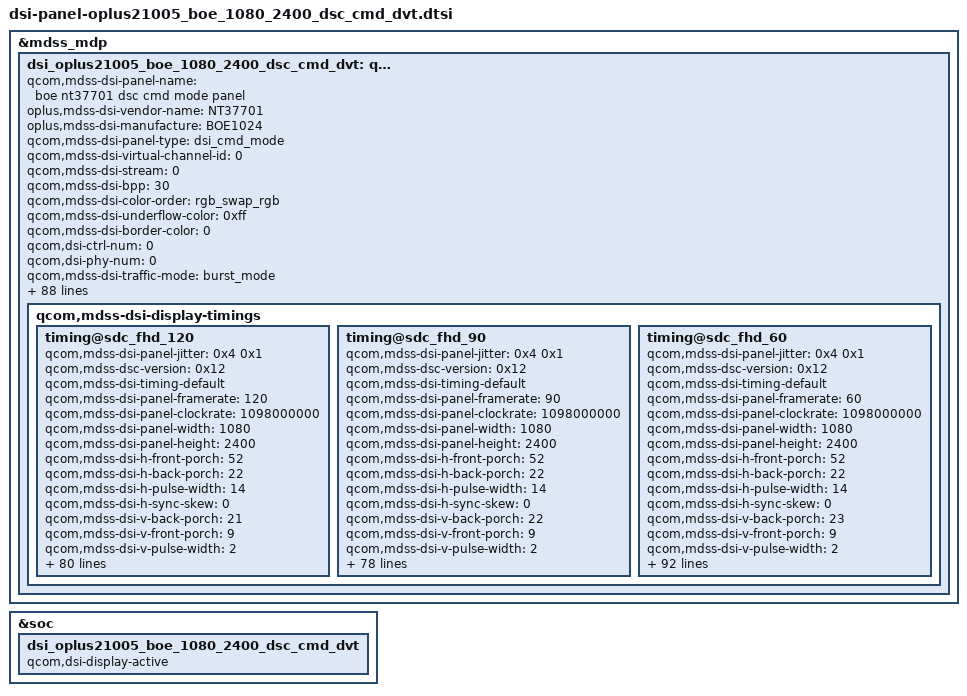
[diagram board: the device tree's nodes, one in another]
&mdss_mdp {
	dsi_oplus21005_boe_1080_2400_dsc_cmd_dvt: qcom,mdss_dsi_oplus21005_boe_1080_2400_dsc_cmd_dvt {
		qcom,mdss-dsi-panel-name = "boe nt37701 dsc cmd mode panel";
		oplus,mdss-dsi-vendor-name = "NT37701";
		oplus,mdss-dsi-manufacture = "BOE1024";
		qcom,mdss-dsi-panel-type = "dsi_cmd_mode";
		qcom,mdss-dsi-virtual-channel-id = <0>;
		qcom,mdss-dsi-stream = <0>;
		qcom,mdss-dsi-bpp = <30>;
		qcom,mdss-dsi-color-order = "rgb_swap_rgb";
		qcom,mdss-dsi-underflow-color = <0xff>;
		qcom,mdss-dsi-border-color = <0>;
		qcom,dsi-ctrl-num = <0>;
		qcom,dsi-phy-num = <0>;
		qcom,mdss-dsi-traffic-mode = "burst_mode";
		qcom,mdss-dsi-lane-map = "lane_map_0123";
		qcom,mdss-dsi-bllp-eof-power-mode;
		qcom,mdss-dsi-bllp-power-mode;
		qcom,mdss-dsi-lane-0-state;
		qcom,mdss-dsi-lane-1-state;
		qcom,mdss-dsi-lane-2-state;
		qcom,mdss-dsi-lane-3-state;
		qcom,mdss-dsi-dma-trigger = "trigger_sw";
		qcom,mdss-loading-effect;
		qcom,mdss-dsi-mdp-trigger = "none";
		qcom,mdss-dsi-reset-sequence = <1 2>, <0 5>, <1 10>;
		qcom,mdss-dsi-te-pin-select = <1>;
		qcom,mdss-dsi-te-dcs-command = <1>;
		qcom,mdss-pan-physical-width-dimension = <68>;
		qcom,mdss-pan-physical-height-dimension = <152>;
		qcom,mdss-dsi-init-delay-us = <1000>;
		qcom,mdss-dsi-te-check-enable;
		qcom,mdss-dsi-te-using-te-pin;
		qcom,mdss-dsi-lp11-init;
		qcom,mdss-dsi-wr-mem-start = <0x2c>;
		qcom,mdss-dsi-wr-mem-continue = <0x3c>;
		qcom,mdss-dsi-panel-jitter = <0x4 0x1>;
		//qcom,mdss-dsc-scr-version = <0x1>;
		qcom,mdss-bl-high2bit;
		/* HDR Setting */
		qcom,mdss-dsi-panel-hdr-enabled;
		qcom,mdss-dsi-panel-hdr-color-primaries = <15635 16450 34000 16000 13250 34500 7500 3000>;
		qcom,mdss-dsi-panel-peak-brightness = <5400000>;
		qcom,mdss-dsi-panel-average-brightness = <2000000>;
		qcom,mdss-dsi-panel-blackness-level = <4000>;

		qcom,esd-check-enabled;
		oplus,esd-check-flag-enabled;
		qcom,mdss-dsi-panel-status-check-mode = "reg_read";
		qcom,mdss-dsi-panel-status-command = [
				06 01 00 01 05 00 02 0A 00
			];
		qcom,mdss-dsi-panel-status-command-state = "dsi_lp_mode";
		qcom,mdss-dsi-panel-status-value = <0x9C>;
		qcom,mdss-dsi-panel-status-read-length = <1>;


		qcom,dynamic-mode-switch-enabled;
		qcom,dynamic-mode-switch-type = "dynamic-resolution-switch-immediate";
		qcom,mdss-dsi-display-timings {
			timing@sdc_fhd_120{
				//qcom,mdss-mdp-transfer-time-us = <7700>;
				qcom,mdss-dsi-panel-jitter = <0x4 0x1>;
				//qcom,mdss-dsc-scr-version = <0x1>;
				qcom,mdss-dsc-version = <0x12>;
				qcom,mdss-dsi-timing-default;
				qcom,mdss-dsi-panel-framerate = <120>;
				//qcom,mdss-dsi-panel-clockrate = <825600000>;
				//qcom,mdss-dsi-panel-clockrate = <960800000>;
				//qcom,mdss-dsi-panel-clockrate = <900000000>;
				qcom,mdss-dsi-panel-clockrate = <1098000000>;
				qcom,mdss-dsi-panel-width = <1080>;
				qcom,mdss-dsi-panel-height = <2400>;

				qcom,mdss-dsi-h-front-porch = <52>;
				qcom,mdss-dsi-h-back-porch = <22>;
				qcom,mdss-dsi-h-pulse-width = <14>;
				qcom,mdss-dsi-h-sync-skew = <0>;
				qcom,mdss-dsi-v-back-porch = <21>;
				qcom,mdss-dsi-v-front-porch = <9>;
				qcom,mdss-dsi-v-pulse-width = <2>;
				qcom,mdss-dsi-h-sync-pulse = <0>;

				qcom,mdss-dsi-h-left-border = <0>;
				qcom,mdss-dsi-h-right-border = <0>;
				qcom,mdss-dsi-v-top-border = <0>;
				qcom,mdss-dsi-v-bottom-border = <0>;

				/* Apollo vsync config, need to measure TE signal */
				oplus,apollo-panel-vsync-width = <2000>;
				oplus,apollo-panel-vsync-period = <8300>;

				qcom,dsi-select-clocks = "mux_byte_clk0", "mux_pixel_clk0";

				oplus,fod-on-vblank = <0>;
				oplus,fod-off-vblank = <0>;
				qcom,mdss-dsi-panel-read-register-open-command = [
					39 01 00 00 00 00 03 F0 5A 5A
					];
				qcom,mdss-dsi-panel-id1-command = [
					06 01 00 00 00 00 01 E9
					];
				qcom,mdss-dsi-panel-read-register-close-command = [
					39 01 00 00 00 00 03 F0 A5 A5
					];
				qcom,mdss-dsi-timing-switch-command = [
					39 01 00 00 00 00 02 2F 03
				];
				qcom,mdss-dsi-on-command=[
					39 01 00 00 00 00 05 FF AA 55 A5 81
					39 01 00 00 00 00 02 6F 0F
					39 01 00 00 00 00 03 FD 01 80
					//39 01 00 00 00 00 06 F0 55 AA 52 08 01
					//39 01 00 00 00 00 08 C3 99 01 98 D0 22 02 00
					//39 01 00 00 00 00 06 F0 55 AA 52 08 01
					//39 01 00 00 00 00 08 C3 97 01 91 D0 22 02 00
					39 01 00 00 00 00 06 F0 55 AA 52 08 01
					39 01 00 00 00 00 08 C3 9C 01 90 D0 22 02 00
					39 01 00 00 00 00 05 FF AA 55 A5 80
					39 01 00 00 00 00 02 35 00
					39 01 00 00 00 00 02 53 20
					39 01 00 00 00 00 05 51 00 00 0F FE
					39 01 00 00 00 00 05 2A 00 00 04 37
					39 01 00 00 00 00 05 2B 00 00 09 5F
					//39 01 00 00 00 00 13 91 89 28 00 14 C2 00 03 1C 02 8C 00 0F 05 0E 02 8B 10 F0
					39 01 00 00 00 00 13 91 AB 2A 00 14 C2 00 02 B0 03 2A 00 15 05 0E 03 1D 0C F0
					39 01 00 00 00 00 02 03 01
					39 01 00 00 00 00 02 90 01
					05 01 00 00 00 00 02 2C 00
					/* Dither off */
					//39 01 00 00 00 00 06 F0 55 AA 52 08 00
					//39 01 00 00 00 00 10 B2 11 00 20 20 00 08 08 00 00 40 30 00 00 00 00

					39 01 00 00 00 00 06 F0 55 AA 52 08 00
					39 01 00 00 00 00 03 B2 11 63

					// SPR setting,pixel layout=GG2R2B
					39 01 00 00 00 00 06 F0 55 AA 52 08 07
					39 01 00 00 00 00 06 B0 8C C0 78 70 00
					39 01 00 00 00 00 06 B1 0c 1c 00 1c 0c
					39 01 00 00 00 00 0A B2 D2 D2 D2 D2 D2 D2 D2 D2 D2
					15 01 00 00 00 00 02 6F 36
					39 01 00 00 00 00 13 B2 32 32 32 32 32 32 32 32 32 05 05 05 05 05 05 05 05 05
					15 01 00 00 00 00 02 6F 09
					39 01 00 00 00 00 0A B2 D2 D2 D2 D2 D2 D2 D2 D2 D2
					15 01 00 00 00 00 02 6F 48
					39 01 00 00 00 00 13 B2 33 33 33 33 33 33 33 33 33 05 05 05 05 05 05 05 05 05
					15 01 00 00 00 00 02 6F 12
					39 01 00 00 00 00 0A B2 00 00 00 00 00 00 00 00 00
					15 01 00 00 00 00 02 6F 5A
					39 01 00 00 00 00 13 B2 04 04 04 04 04 04 04 04 04 04 04 04 04 04 04 04 04 04

					15 01 00 00 00 00 02 6F 1B
					39 01 00 00 00 00 0A B2 D2 D2 D2 D2 D2 D2 D2 D2 D2
					15 01 00 00 00 00 02 6F 6C
					39 01 00 00 00 00 13 B2 33 33 33 33 33 33 33 33 33 05 05 05 05 05 05 05 05 05

					15 01 00 00 00 00 02 6F 24
					39 01 00 00 00 00 0A B2 D2 D2 D2 D2 D2 D2 D2 D2 D2
					15 01 00 00 00 00 02 6F 7E
					39 01 00 00 00 00 13 B2 32 32 32 32 32 32 32 32 32 05 05 05 05 05 05 05 05 05

					15 01 00 00 00 00 02 6F 2D
					39 01 00 00 00 00 0A B2 00 00 00 00 00 00 00 00 00
					15 01 00 00 00 00 02 6F 90
					39 01 00 00 00 00 13 B2 04 04 04 04 04 04 04 04 04 04 04 04 04 04 04 04 04 04
					39 01 00 00 00 00 03 B7 00 00

					// SPR panel boundary decolor
					15 01 00 00 00 00 02 B4 C0
					15 01 00 00 00 00 02 6F 01
					39 01 00 00 00 00 0D B4 80 70 80 75 35 80 30 80 75 80 60 80

					// SPR FT OFF
					39 01 00 00 00 00 03 B7 00 00

					39 01 00 00 00 00 02 82 AE
					//39 01 00 00 00 00 02 8B 80
					39 01 00 00 00 00 02 2F 03
					39 01 00 00 00 00 06 F0 55 AA 52 08 01
					39 01 00 00 00 00 03 CD 05 81
					39 01 00 00 00 00 02 6F 10
					39 01 00 00 00 00 02 D8 14
					39 01 00 00 00 00 06 F0 55 AA 52 08 00
					39 01 00 00 00 00 02 6F 01
					39 01 00 00 00 00 02 C0 B3
					39 01 00 00 00 00 05 FF AA 55 A5 80
					39 01 00 00 00 00 02 6F 2E
					39 01 00 00 00 00 02 FB D1
					05 01 00 00 78 00 02 11 00
				];
				qcom,mdss-dsi-post-on-backlight = [
					/* Display On */
					05 01 00 00 00 00 02 29 00
				];
				qcom,mdss-dsi-off-command=[
					39 01 00 00 00 00 06 F0 55 AA 52 08 01
					15 01 00 00 00 00 02 CE 0C
					05 01 00 00 0A 00 02 28 00
					05 01 00 00 FA 00 02 10 00
				];
				qcom,mdss-dsi-lp1-command = [
					/* Panel OFF */
					05 01 00 00 11 00 01 28
					/* AOD Mode ON Setting */
					39 01 00 00 00 00 06 F0 55 AA 52 08 00
					15 01 00 00 00 00 02 6F 0D
					15 01 00 00 00 00 02 B5 50
					15 01 00 00 00 00 02 2F 01
					05 01 00 00 00 00 01 39
					05 01 00 00 14 00 01 2C
					15 01 00 00 00 00 02 65 01
					05 01 00 00 00 00 01 29
				];
				qcom,mdss-dsi-nolp-command = [
					/* AOD OFF */
					39 01 00 00 00 00 06 F0 55 AA 52 08 00
					15 01 00 00 00 00 02 6F 0D
					15 01 00 00 00 00 02 B5 4F
					15 01 00 00 00 00 02 65 00
					05 01 00 00 00 00 01 38
					05 01 00 00 14 00 01 2C
					15 01 00 00 00 00 02 2F 03

					/* ELVSS DIM OFF
					39 01 00 00 00 00 03 F0 5A 5A
					39 01 00 00 00 00 04 B0 00 0C 63
					15 01 00 00 00 00 02 63 00
					39 01 00 00 00 00 03 F0 A5 A5*/

					/* HBM OFF Mode
					39 01 00 00 00 00 06 F0 55 AA 52 08 00
					15 01 00 00 00 00 02 B2 11 */
				];
				qcom,mdss-dsi-aod-hbm-on-command = [
					/* Loading OFF
					39 00 00 00 00 00 03 F0 5A 5A
					39 00 00 00 00 00 04 B0 02 B6 1D
					39 00 00 00 00 00 02 1D 05
					39 01 00 00 00 00 03 F0 A5 A5*/
					/* AOD OFF */
					39 01 00 00 00 00 06 F0 55 AA 52 08 00
					15 01 00 00 00 00 02 6F 0D
					15 01 00 00 00 00 02 B5 4F
					15 01 00 00 00 00 02 65 00
					05 01 00 00 00 00 01 38
					05 01 00 00 00 00 01 2C
					/* AOR 1.6%
					39 00 00 00 00 00 03 F0 5A 5A
					39 00 00 00 00 00 04 B0 00 01 BD
					39 00 00 00 00 00 02 BD 02
					39 00 00 00 00 00 04 B0 02 b9 65
					39 00 00 00 00 00 07 65 00 AC 00 AC 00 AC
					39 00 00 00 00 00 02 F7 0F
					39 01 00 00 00 00 03 F0 A5 A5*/
					/* Hbm ON */
					39 01 00 00 00 00 03 51 0F FF
				];
				qcom,mdss-dsi-aod-hbm-off-command = [
					/* HBM OFF Mode
					39 01 00 00 00 00 06 F0 55 AA 52 08 00
					15 01 00 00 00 00 02 B2 11 */
				    /* AOD ON */
					39 01 00 00 00 00 06 F0 55 AA 52 08 00
					15 01 00 00 00 00 02 6F 0D
					15 01 00 00 00 00 02 B5 50
					15 01 00 00 00 00 02 2F 01
					05 01 00 00 00 00 01 39
					05 01 00 00 14 00 01 2C
					15 01 00 00 00 00 02 65 01
					05 01 00 00 00 00 01 29
					/* AOD 50nit */
					39 01 00 00 00 00 06 F0 55 AA 52 08 00
					15 01 00 00 00 00 02 6F 26
					39 01 00 00 00 00 0B B4 04 A2 04 A2 04 A2 04 A2 04 A2
				];
				qcom,mdss-dsi-hbm-off-command = [
					/* HBM OFF Mode
					39 01 00 00 00 00 06 F0 55 AA 52 08 00
					15 01 00 00 00 00 02 B2 11 */
				];
				qcom,mdss-dsi-hbm-on-command = [
					39 01 00 00 00 00 03 51 0F FF
				];
				qcom,mdss-dsi-normal-hbm-on-command = [
					39 01 00 00 00 00 03 51 0F FF
				];
				qcom,mdss-dsi-hbm-enter-switch-command = [
					39 01 00 00 00 00 03 51 0F FF
				];
				qcom,mdss-dsi-hbm-exit-switch-command = [
					/* HBM OFF Mode
					39 01 00 00 00 00 06 F0 55 AA 52 08 00
					15 01 00 00 00 00 02 B2 11 */
				];
				qcom,mdss-dsi-aor-restore-command = [
					/* AOR 16% */
					39 00 00 00 00 00 03 f0 5a 5a
					39 00 00 00 00 00 04 b0 00 01 bd
					39 00 00 00 00 00 02 bd 02
					39 00 00 00 00 00 04 b0 02 b9 65
					39 00 00 00 00 00 07 65 01 5e 01 5e 01 5e
					39 00 00 00 00 00 02 f7 0f
					39 01 00 00 00 00 03 f0 a5 a5
				];
				qcom,mdss-dsi-aod-high-mode-command = [
					/* AOD 50nit */
					39 01 00 00 00 00 06 F0 55 AA 52 08 00
					15 01 00 00 00 00 02 6F 26
					39 01 00 00 00 00 0B B4 04 A2 04 A2 04 A2 04 A2 04 A2
				];
				qcom,mdss-dsi-aod-low-mode-command = [
					/* AOD 10nit */
					39 01 00 00 00 00 06 F0 55 AA 52 08 00
					15 01 00 00 00 00 02 6F 26
					39 01 00 00 00 00 0B B4 08 8A 08 8A 08 8A 08 8A 08 8A
				];
				qcom,mdss-dsi-esd-switch-page-command = [
					39 01 00 00 00 00 05 FF AA 55 A5 81
					15 01 00 00 00 00 02 6F 0F
				];

				qcom,mdss-dsi-aod-hbm-on-command-state = "dsi_hs_mode";
				qcom,mdss-dsi-aod-hbm-off-command-state = "dsi_hs_mode";
				qcom,mdss-dsi-timing-switch-command-state = "dsi_hs_mode";
				qcom,mdss-dsi-on-command-state = "dsi_lp_mode";
				qcom,mdss-dsi-off-command-state = "dsi_hs_mode";
				/*
				qcom,mdss-dsi-seed-off-command-state = "dsi_hs_mode";
				qcom,mdss-dsi-seed-0-command-state = "dsi_hs_mode";
				qcom,mdss-dsi-seed-1-command-state = "dsi_hs_mode";
				qcom,mdss-dsi-seed-2-command-state = "dsi_hs_mode";
				qcom,mdss-dsi-loading-effect-1-command-state = "dsi_hs_mode";
				qcom,mdss-dsi-loading-effect-2-command-state = "dsi_hs_mode";
				qcom,mdss-dsi-loading-effect-off-command-state = "dsi_hs_mode";
				*/
				qcom,mdss-dsi-hbm-on-command-state = "dsi_hs_mode";
				qcom,mdss-dsi-hbm-off-command-state = "dsi_hs_mode";
				qcom,mdss-dsi-aor-restore-command-state = "dsi_hs_mode";

				//qcom,lm-split = <540 540>;
				qcom,compression-mode = "dsc";
				//qcom,mdss-dsc-encoders = <2>;
				qcom,mdss-dsc-slice-height = <20>;
				qcom,mdss-dsc-slice-width = <1080>;
				qcom,mdss-dsc-slice-per-pkt = <1>;
				qcom,mdss-dsc-bit-per-component = <10>;
				qcom,mdss-dsc-bit-per-pixel = <10>;
				qcom,mdss-dsc-block-prediction-enable;
				qcom,mdss-dsi-panel-id1-command-state = "dsi_lp_mode";
				qcom,mdss-dsi-panel-read-register-open-state = "dsi_lp_mode";
				qcom,mdss-dsi-panel-read-register-close-state = "dsi_lp_mode";
			};
			timing@sdc_fhd_90{
				//qcom,mdss-mdp-transfer-time-us = <7700>;
				qcom,mdss-dsi-panel-jitter = <0x4 0x1>;
				//qcom,mdss-dsc-scr-version = <0x1>;
				qcom,mdss-dsc-version = <0x12>;
				qcom,mdss-dsi-timing-default;
				qcom,mdss-dsi-panel-framerate = <90>;
				//qcom,mdss-dsi-panel-clockrate = <825600000>;
				//qcom,mdss-dsi-panel-clockrate = <960800000>;
				//qcom,mdss-dsi-panel-clockrate = <900000000>;
				qcom,mdss-dsi-panel-clockrate = <1098000000>;
				qcom,mdss-dsi-panel-width = <1080>;
				qcom,mdss-dsi-panel-height = <2400>;

				qcom,mdss-dsi-h-front-porch = <52>;
				qcom,mdss-dsi-h-back-porch = <22>;
				qcom,mdss-dsi-h-pulse-width = <14>;
				qcom,mdss-dsi-h-sync-skew = <0>;
				qcom,mdss-dsi-v-back-porch = <22>;
				qcom,mdss-dsi-v-front-porch = <9>;
				qcom,mdss-dsi-v-pulse-width = <2>;
				qcom,mdss-dsi-h-sync-pulse = <0>;

				qcom,mdss-dsi-h-left-border = <0>;
				qcom,mdss-dsi-h-right-border = <0>;
				qcom,mdss-dsi-v-top-border = <0>;
				qcom,mdss-dsi-v-bottom-border = <0>;

				qcom,dsi-select-clocks = "mux_byte_clk0", "mux_pixel_clk0";

				oplus,fod-on-vblank = <0>;
				oplus,fod-off-vblank = <0>;
				qcom,mdss-dsi-panel-read-register-open-command = [
					39 01 00 00 00 00 03 F0 5A 5A
					];
				qcom,mdss-dsi-panel-id1-command = [
					06 01 00 00 00 00 01 E9
					];
				qcom,mdss-dsi-panel-read-register-close-command = [
					39 01 00 00 00 00 03 F0 A5 A5
					];
				qcom,mdss-dsi-timing-switch-command = [
					39 01 00 00 02 00 02 2F 02
				];
				qcom,mdss-dsi-on-command=[
					39 01 00 00 00 00 05 FF AA 55 A5 81
					39 01 00 00 00 00 02 6F 0F
					39 01 00 00 00 00 03 FD 01 80
					//39 01 00 00 00 00 06 F0 55 AA 52 08 01
					//39 01 00 00 00 00 08 C3 99 01 98 D0 22 02 00
					//39 01 00 00 00 00 06 F0 55 AA 52 08 01
					//39 01 00 00 00 00 08 C3 97 01 91 D0 22 02 00
					39 01 00 00 00 00 06 F0 55 AA 52 08 01
					39 01 00 00 00 00 08 C3 9C 01 90 D0 22 02 00
					39 01 00 00 00 00 05 FF AA 55 A5 80
					39 01 00 00 00 00 02 35 00
					39 01 00 00 00 00 02 53 20
					39 01 00 00 00 00 05 51 00 00 0F FE
					39 01 00 00 00 00 05 2A 00 00 04 37
					39 01 00 00 00 00 05 2B 00 00 09 5F
					//39 01 00 00 00 00 13 91 89 28 00 14 C2 00 03 1C 02 8C 00 0F 05 0E 02 8B 10 F0
					39 01 00 00 00 00 13 91 AB 2A 00 14 C2 00 02 B0 03 2A 00 15 05 0E 03 1D 0C F0
					39 01 00 00 00 00 02 03 01
					39 01 00 00 00 00 02 90 01
					05 01 00 00 00 00 02 2C 00
					/* Dither off */
					//39 01 00 00 00 00 06 F0 55 AA 52 08 00
					//39 01 00 00 00 00 10 B2 11 00 20 20 00 08 08 00 00 40 30 00 00 00 00

					39 01 00 00 00 00 06 F0 55 AA 52 08 00
					39 01 00 00 00 00 03 B2 11 63

					// SPR setting,pixel layout=GG2R2B
					39 01 00 00 00 00 06 F0 55 AA 52 08 07
					39 01 00 00 00 00 06 B0 8C C0 78 70 00
					39 01 00 00 00 00 06 B1 0c 1c 00 1c 0c
					39 01 00 00 00 00 0A B2 D2 D2 D2 D2 D2 D2 D2 D2 D2
					15 01 00 00 00 00 02 6F 36
					39 01 00 00 00 00 13 B2 32 32 32 32 32 32 32 32 32 05 05 05 05 05 05 05 05 05
					15 01 00 00 00 00 02 6F 09
					39 01 00 00 00 00 0A B2 D2 D2 D2 D2 D2 D2 D2 D2 D2
					15 01 00 00 00 00 02 6F 48
					39 01 00 00 00 00 13 B2 33 33 33 33 33 33 33 33 33 05 05 05 05 05 05 05 05 05
					15 01 00 00 00 00 02 6F 12
					39 01 00 00 00 00 0A B2 00 00 00 00 00 00 00 00 00
					15 01 00 00 00 00 02 6F 5A
					39 01 00 00 00 00 13 B2 04 04 04 04 04 04 04 04 04 04 04 04 04 04 04 04 04 04

					15 01 00 00 00 00 02 6F 1B
					39 01 00 00 00 00 0A B2 D2 D2 D2 D2 D2 D2 D2 D2 D2
					15 01 00 00 00 00 02 6F 6C
					39 01 00 00 00 00 13 B2 33 33 33 33 33 33 33 33 33 05 05 05 05 05 05 05 05 05

					15 01 00 00 00 00 02 6F 24
					39 01 00 00 00 00 0A B2 D2 D2 D2 D2 D2 D2 D2 D2 D2
					15 01 00 00 00 00 02 6F 7E
					39 01 00 00 00 00 13 B2 32 32 32 32 32 32 32 32 32 05 05 05 05 05 05 05 05 05

					15 01 00 00 00 00 02 6F 2D
					39 01 00 00 00 00 0A B2 00 00 00 00 00 00 00 00 00
					15 01 00 00 00 00 02 6F 90
					39 01 00 00 00 00 13 B2 04 04 04 04 04 04 04 04 04 04 04 04 04 04 04 04 04 04
					39 01 00 00 00 00 03 B7 00 00

					// SPR panel boundary decolor
					15 01 00 00 00 00 02 B4 C0
					15 01 00 00 00 00 02 6F 01
					39 01 00 00 00 00 0D B4 80 70 80 75 35 80 30 80 75 80 60 80

					// SPR FT OFF
					39 01 00 00 00 00 03 B7 00 00

					39 01 00 00 00 00 02 82 AE
					//39 01 00 00 00 00 02 8B 80
					39 01 00 00 00 00 02 2F 02
					39 01 00 00 00 00 06 F0 55 AA 52 08 01
					39 01 00 00 00 00 03 CD 05 81
					39 01 00 00 00 00 02 6F 10
					39 01 00 00 00 00 02 D8 14
					39 01 00 00 00 00 06 F0 55 AA 52 08 00
					39 01 00 00 00 00 02 6F 01
					39 01 00 00 00 00 02 C0 B3
					39 01 00 00 00 00 05 FF AA 55 A5 80
					39 01 00 00 00 00 02 6F 2E
					39 01 00 00 00 00 02 FB D1
					05 01 00 00 78 00 02 11 00
				];
				qcom,mdss-dsi-post-on-backlight = [
					/* Display On */
					05 01 00 00 00 00 02 29 00
				];
				qcom,mdss-dsi-off-command=[
					39 01 00 00 00 00 06 F0 55 AA 52 08 01
					15 01 00 00 00 00 02 CE 0C
					05 01 00 00 0A 00 02 28 00
					05 01 00 00 FA 00 02 10 00
				];
				qcom,mdss-dsi-lp1-command = [
					/* Panel OFF */
					05 01 00 00 11 00 01 28
					/* AOD Mode ON Setting */
					39 01 00 00 00 00 06 F0 55 AA 52 08 00
					15 01 00 00 00 00 02 6F 0D
					15 01 00 00 00 00 02 B5 50
					15 01 00 00 00 00 02 2F 01
					05 01 00 00 00 00 01 39
					05 01 00 00 14 00 01 2C
					15 01 00 00 00 00 02 65 01
					05 01 00 00 00 00 01 29
				];
				qcom,mdss-dsi-nolp-command = [
					/* AOD OFF */
					39 01 00 00 00 00 06 F0 55 AA 52 08 00
					15 01 00 00 00 00 02 6F 0D
					15 01 00 00 00 00 02 B5 4F
					15 01 00 00 00 00 02 65 00
					05 01 00 00 00 00 01 38
					05 01 00 00 00 00 01 2C
					15 01 00 00 00 00 02 2F 02

					/* ELVSS DIM OFF
					39 01 00 00 00 00 03 F0 5A 5A
					39 01 00 00 00 00 04 B0 00 0C 63
					15 01 00 00 00 00 02 63 00
					39 01 00 00 00 00 03 F0 A5 A5*/

					/* HBM OFF Mode
					39 01 00 00 00 00 06 F0 55 AA 52 08 00
					15 01 00 00 00 00 02 B2 11 */
				];
				qcom,mdss-dsi-aod-hbm-on-command = [
					/* Loading OFF
					39 00 00 00 00 00 03 F0 5A 5A
					39 00 00 00 00 00 04 B0 02 B6 1D
					39 00 00 00 00 00 02 1D 05
					39 01 00 00 00 00 03 F0 A5 A5*/
					/* AOD OFF */
					39 01 00 00 00 00 06 F0 55 AA 52 08 00
					15 01 00 00 00 00 02 6F 0D
					15 01 00 00 00 00 02 B5 4F
					15 01 00 00 00 00 02 65 00
					05 01 00 00 00 00 01 38
					05 01 00 00 00 00 01 2C
					/* AOR 1.6%
					39 00 00 00 00 00 03 F0 5A 5A
					39 00 00 00 00 00 04 B0 00 01 BD
					39 00 00 00 00 00 02 BD 02
					39 00 00 00 00 00 04 B0 02 b9 65
					39 00 00 00 00 00 07 65 00 AC 00 AC 00 AC
					39 00 00 00 00 00 02 F7 0F
					39 01 00 00 00 00 03 F0 A5 A5*/
					/* Hbm ON */
					39 01 00 00 00 00 03 51 0F FF
				];
				qcom,mdss-dsi-aod-hbm-off-command = [
					/* HBM OFF Mode
					39 01 00 00 00 00 06 F0 55 AA 52 08 00
					15 01 00 00 00 00 02 B2 11 */
					/* AOD ON */
					39 01 00 00 00 00 06 F0 55 AA 52 08 00
					15 01 00 00 00 00 02 6F 0D
					15 01 00 00 00 00 02 B5 50
					15 01 00 00 00 00 02 2F 01
					05 01 00 00 00 00 01 39
					05 01 00 00 14 00 01 2C
					15 01 00 00 00 00 02 65 01
					05 01 00 00 00 00 01 29
					/* AOD 50nit */
					39 01 00 00 00 00 06 F0 55 AA 52 08 00
					15 01 00 00 00 00 02 6F 26
					39 01 00 00 00 00 0B B4 04 A2 04 A2 04 A2 04 A2 04 A2
				];
				qcom,mdss-dsi-hbm-off-command = [
					/* HBM OFF Mode
					39 01 00 00 00 00 06 F0 55 AA 52 08 00
					15 01 00 00 00 00 02 B2 11 */
				];
				qcom,mdss-dsi-hbm-on-command = [
					39 01 00 00 00 00 03 51 0F FF
				];
				qcom,mdss-dsi-normal-hbm-on-command = [
					39 01 00 00 00 00 03 51 0F FF
				];
				qcom,mdss-dsi-hbm-enter-switch-command = [
					39 01 00 00 00 00 03 51 0F FF
				];
				qcom,mdss-dsi-hbm-exit-switch-command = [
					/* HBM OFF Mode
					39 01 00 00 00 00 06 F0 55 AA 52 08 00
					15 01 00 00 00 00 02 B2 11 */
				];
				qcom,mdss-dsi-aor-restore-command = [
					/* AOR 16% */
					39 00 00 00 00 00 03 f0 5a 5a
					39 00 00 00 00 00 04 b0 00 01 bd
					39 00 00 00 00 00 02 bd 02
					39 00 00 00 00 00 04 b0 02 b9 65
					39 00 00 00 00 00 07 65 01 5e 01 5e 01 5e
					39 00 00 00 00 00 02 f7 0f
					39 01 00 00 00 00 03 f0 a5 a5
				];
				qcom,mdss-dsi-aod-high-mode-command = [
					/* AOD 50nit */
					39 01 00 00 00 00 06 F0 55 AA 52 08 00
					15 01 00 00 00 00 02 6F 26
					39 01 00 00 00 00 0B B4 04 A2 04 A2 04 A2 04 A2 04 A2
				];
				qcom,mdss-dsi-aod-low-mode-command = [
					/* AOD 10nit */
					39 01 00 00 00 00 06 F0 55 AA 52 08 00
					15 01 00 00 00 00 02 6F 26
					39 01 00 00 00 00 0B B4 08 8A 08 8A 08 8A 08 8A 08 8A
				];
				qcom,mdss-dsi-esd-switch-page-command = [
					39 01 00 00 00 00 05 FF AA 55 A5 81
					15 01 00 00 00 00 02 6F 0F
				];

				qcom,mdss-dsi-aod-hbm-on-command-state = "dsi_hs_mode";
				qcom,mdss-dsi-aod-hbm-off-command-state = "dsi_hs_mode";
				qcom,mdss-dsi-timing-switch-command-state = "dsi_hs_mode";
				qcom,mdss-dsi-on-command-state = "dsi_lp_mode";
				qcom,mdss-dsi-off-command-state = "dsi_hs_mode";
				/*
				qcom,mdss-dsi-seed-off-command-state = "dsi_hs_mode";
				qcom,mdss-dsi-seed-0-command-state = "dsi_hs_mode";
				qcom,mdss-dsi-seed-1-command-state = "dsi_hs_mode";
				qcom,mdss-dsi-seed-2-command-state = "dsi_hs_mode";
				qcom,mdss-dsi-loading-effect-1-command-state = "dsi_hs_mode";
				qcom,mdss-dsi-loading-effect-2-command-state = "dsi_hs_mode";
				qcom,mdss-dsi-loading-effect-off-command-state = "dsi_hs_mode";
				*/
				qcom,mdss-dsi-hbm-on-command-state = "dsi_hs_mode";
				qcom,mdss-dsi-hbm-off-command-state = "dsi_hs_mode";
				qcom,mdss-dsi-aor-restore-command-state = "dsi_hs_mode";

				//qcom,lm-split = <540 540>;
				qcom,compression-mode = "dsc";
				//qcom,mdss-dsc-encoders = <2>;
				qcom,mdss-dsc-slice-height = <20>;
				qcom,mdss-dsc-slice-width = <1080>;
				qcom,mdss-dsc-slice-per-pkt = <1>;
				qcom,mdss-dsc-bit-per-component = <10>;
				qcom,mdss-dsc-bit-per-pixel = <10>;
				qcom,mdss-dsc-block-prediction-enable;
				qcom,mdss-dsi-panel-id1-command-state = "dsi_lp_mode";
				qcom,mdss-dsi-panel-read-register-open-state = "dsi_lp_mode";
				qcom,mdss-dsi-panel-read-register-close-state = "dsi_lp_mode";
			};
			timing@sdc_fhd_60{
				//qcom,mdss-mdp-transfer-time-us = <7700>;
				qcom,mdss-dsi-panel-jitter = <0x4 0x1>;
				//qcom,mdss-dsc-scr-version = <0x1>;
				qcom,mdss-dsc-version = <0x12>;
				qcom,mdss-dsi-timing-default;
				qcom,mdss-dsi-panel-framerate = <60>;
				//qcom,mdss-dsi-panel-clockrate = <825600000>;
				//qcom,mdss-dsi-panel-clockrate = <960800000>;
				//qcom,mdss-dsi-panel-clockrate = <900000000>;
				qcom,mdss-dsi-panel-clockrate = <1098000000>;
				qcom,mdss-dsi-panel-width = <1080>;
				qcom,mdss-dsi-panel-height = <2400>;

				qcom,mdss-dsi-h-front-porch = <52>;
				qcom,mdss-dsi-h-back-porch = <22>;
				qcom,mdss-dsi-h-pulse-width = <14>;
				qcom,mdss-dsi-h-sync-skew = <0>;
				qcom,mdss-dsi-v-back-porch = <23>;
				qcom,mdss-dsi-v-front-porch = <9>;
				qcom,mdss-dsi-v-pulse-width = <2>;
				qcom,mdss-dsi-h-sync-pulse = <0>;

				qcom,mdss-dsi-h-left-border = <0>;
				qcom,mdss-dsi-h-right-border = <0>;
				qcom,mdss-dsi-v-top-border = <0>;
				qcom,mdss-dsi-v-bottom-border = <0>;

				/* Apollo vsync config, need to measure TE signal */
				oplus,apollo-panel-vsync-width = <13000>;
				oplus,apollo-panel-vsync-period = <16600>;

				qcom,dsi-select-clocks = "mux_byte_clk0", "mux_pixel_clk0";

				oplus,fod-on-vblank = <0>;
				oplus,fod-off-vblank = <0>;
				qcom,mdss-dsi-panel-read-register-open-command = [
					39 01 00 00 00 00 03 F0 5A 5A
					];
				qcom,mdss-dsi-panel-id1-command = [
					06 01 00 00 00 00 01 E9
					];
				qcom,mdss-dsi-panel-read-register-close-command = [
					39 01 00 00 00 00 03 F0 A5 A5
					];
				qcom,mdss-dsi-timing-switch-command = [
					39 01 00 00 02 00 02 2F 01
					];
				qcom,mdss-dsi-on-command=[
					39 01 00 00 00 00 05 FF AA 55 A5 81
					39 01 00 00 00 00 02 6F 0F
					39 01 00 00 00 00 03 FD 01 80
					//39 01 00 00 00 00 06 F0 55 AA 52 08 01
					//39 01 00 00 00 00 08 C3 99 01 98 D0 22 02 00
					//39 01 00 00 00 00 06 F0 55 AA 52 08 01
					//39 01 00 00 00 00 08 C3 97 01 91 D0 22 02 00
					39 01 00 00 00 00 06 F0 55 AA 52 08 01
					39 01 00 00 00 00 08 C3 9C 01 90 D0 22 02 00
					39 01 00 00 00 00 05 FF AA 55 A5 80
					39 01 00 00 00 00 02 35 00
					39 01 00 00 00 00 02 53 20
					39 01 00 00 00 00 05 51 00 00 0F FE
					39 01 00 00 00 00 05 2A 00 00 04 37
					39 01 00 00 00 00 05 2B 00 00 09 5F
					//39 01 00 00 00 00 13 91 89 28 00 14 C2 00 03 1C 02 8C 00 0F 05 0E 02 8B 10 F0
					39 01 00 00 00 00 13 91 AB 2A 00 14 C2 00 02 B0 03 2A 00 15 05 0E 03 1D 0C F0
					39 01 00 00 00 00 02 03 01
					39 01 00 00 00 00 02 90 01
					05 01 00 00 00 00 02 2C 00
					/* Dither off */
					//39 01 00 00 00 00 06 F0 55 AA 52 08 00
					//39 01 00 00 00 00 10 B2 11 00 20 20 00 08 08 00 00 40 30 00 00 00 00

					39 01 00 00 00 00 06 F0 55 AA 52 08 00
					39 01 00 00 00 00 03 B2 11 63

					// SPR setting,pixel layout=GG2R2B
					39 01 00 00 00 00 06 F0 55 AA 52 08 07
					39 01 00 00 00 00 06 B0 8C C0 78 70 00
					39 01 00 00 00 00 06 B1 0c 1c 00 1c 0c
					39 01 00 00 00 00 0A B2 D2 D2 D2 D2 D2 D2 D2 D2 D2
					15 01 00 00 00 00 02 6F 36
					39 01 00 00 00 00 13 B2 32 32 32 32 32 32 32 32 32 05 05 05 05 05 05 05 05 05
					15 01 00 00 00 00 02 6F 09
					39 01 00 00 00 00 0A B2 D2 D2 D2 D2 D2 D2 D2 D2 D2
					15 01 00 00 00 00 02 6F 48
					39 01 00 00 00 00 13 B2 33 33 33 33 33 33 33 33 33 05 05 05 05 05 05 05 05 05
					15 01 00 00 00 00 02 6F 12
					39 01 00 00 00 00 0A B2 00 00 00 00 00 00 00 00 00
					15 01 00 00 00 00 02 6F 5A
					39 01 00 00 00 00 13 B2 04 04 04 04 04 04 04 04 04 04 04 04 04 04 04 04 04 04

					15 01 00 00 00 00 02 6F 1B
					39 01 00 00 00 00 0A B2 D2 D2 D2 D2 D2 D2 D2 D2 D2
					15 01 00 00 00 00 02 6F 6C
					39 01 00 00 00 00 13 B2 33 33 33 33 33 33 33 33 33 05 05 05 05 05 05 05 05 05

					15 01 00 00 00 00 02 6F 24
					39 01 00 00 00 00 0A B2 D2 D2 D2 D2 D2 D2 D2 D2 D2
					15 01 00 00 00 00 02 6F 7E
					39 01 00 00 00 00 13 B2 32 32 32 32 32 32 32 32 32 05 05 05 05 05 05 05 05 05

					15 01 00 00 00 00 02 6F 2D
					39 01 00 00 00 00 0A B2 00 00 00 00 00 00 00 00 00
					15 01 00 00 00 00 02 6F 90
					39 01 00 00 00 00 13 B2 04 04 04 04 04 04 04 04 04 04 04 04 04 04 04 04 04 04
					39 01 00 00 00 00 03 B7 00 00

					// SPR panel boundary decolor
					15 01 00 00 00 00 02 B4 C0
					15 01 00 00 00 00 02 6F 01
					39 01 00 00 00 00 0D B4 80 70 80 75 35 80 30 80 75 80 60 80

					// SPR FT OFF
					39 01 00 00 00 00 03 B7 00 00

					39 01 00 00 00 00 02 82 AE
					//39 01 00 00 00 00 02 8B 80
					39 01 00 00 00 00 02 2F 01
					39 01 00 00 00 00 06 F0 55 AA 52 08 01
					39 01 00 00 00 00 03 CD 05 81
					39 01 00 00 00 00 02 6F 10
					39 01 00 00 00 00 02 D8 14
					39 01 00 00 00 00 06 F0 55 AA 52 08 00
					39 01 00 00 00 00 02 6F 01
					39 01 00 00 00 00 02 C0 B3
					39 01 00 00 00 00 05 FF AA 55 A5 80
					39 01 00 00 00 00 02 6F 2E
					39 01 00 00 00 00 02 FB D1
					05 01 00 00 78 00 02 11 00
				];
				qcom,mdss-dsi-post-on-backlight = [
					/* Display On */
					05 01 00 00 00 00 02 29 00
				];
				qcom,mdss-dsi-off-command=[
					39 01 00 00 00 00 06 F0 55 AA 52 08 01
					15 01 00 00 00 00 02 CE 0C
					05 01 00 00 0A 00 02 28 00
					05 01 00 00 FA 00 02 10 00
				];
				qcom,mdss-dsi-lp1-command = [
					/* Panel OFF */
					05 01 00 00 11 00 01 28
					/* AOD Mode ON Setting */
					39 01 00 00 00 00 06 F0 55 AA 52 08 00
					15 01 00 00 00 00 02 6F 0D
					15 01 00 00 00 00 02 B5 50
					15 01 00 00 00 00 02 2F 01
					05 01 00 00 00 00 01 39
					05 01 00 00 14 00 01 2C
					15 01 00 00 00 00 02 65 01
					05 01 00 00 00 00 01 29
				];
				qcom,mdss-dsi-nolp-command = [
					/* AOD OFF */
					39 01 00 00 00 00 06 F0 55 AA 52 08 00
					15 01 00 00 00 00 02 6F 0D
					15 01 00 00 00 00 02 B5 4F
					15 01 00 00 00 00 02 65 00
					05 01 00 00 00 00 01 38
					05 01 00 00 00 00 01 2C
					15 01 00 00 00 00 02 2F 01

					/* ELVSS DIM OFF
					39 01 00 00 00 00 03 F0 5A 5A
					39 01 00 00 00 00 04 B0 00 0C 63
					15 01 00 00 00 00 02 63 00
					39 01 00 00 00 00 03 F0 A5 A5*/

					/* HBM OFF Mode
					39 01 00 00 00 00 06 F0 55 AA 52 08 00
					15 01 00 00 00 00 02 B2 11 */
				];
				qcom,mdss-dsi-aod-hbm-on-command = [
					/* Loading OFF
					39 00 00 00 00 00 03 F0 5A 5A
					39 00 00 00 00 00 04 B0 02 B6 1D
					39 00 00 00 00 00 02 1D 05
					39 01 00 00 00 00 03 F0 A5 A5*/
					/* AOD OFF */
					39 01 00 00 00 00 06 F0 55 AA 52 08 00
					15 01 00 00 00 00 02 6F 0D
					15 01 00 00 00 00 02 B5 4F
					15 01 00 00 00 00 02 65 00
					05 01 00 00 00 00 01 38
					05 01 00 00 00 00 01 2C
					/* AOR 1.6%
					39 00 00 00 00 00 03 F0 5A 5A
					39 00 00 00 00 00 04 B0 00 01 BD
					39 00 00 00 00 00 02 BD 02
					39 00 00 00 00 00 04 B0 02 b9 65
					39 00 00 00 00 00 07 65 00 AC 00 AC 00 AC
					39 00 00 00 00 00 02 F7 0F
					39 01 00 00 00 00 03 F0 A5 A5*/
					/* Hbm ON */
					39 01 00 00 00 00 03 51 0F FF
				];
				qcom,mdss-dsi-aod-hbm-off-command = [
					/* HBM OFF Mode
					39 01 00 00 00 00 06 F0 55 AA 52 08 00
					15 01 00 00 00 00 02 B2 11 */
					/* AOD ON */
					39 01 00 00 00 00 06 F0 55 AA 52 08 00
					15 01 00 00 00 00 02 6F 0D
					15 01 00 00 00 00 02 B5 50
					15 01 00 00 00 00 02 2F 01
					05 01 00 00 00 00 01 39
					05 01 00 00 14 00 01 2C
					15 01 00 00 00 00 02 65 01
					05 01 00 00 00 00 01 29
					/* AOD 50nit */
					39 01 00 00 00 00 06 F0 55 AA 52 08 00
					15 01 00 00 00 00 02 6F 26
					39 01 00 00 00 00 0B B4 04 A2 04 A2 04 A2 04 A2 04 A2
				];
				qcom,mdss-dsi-hbm-off-command = [
					/* HBM OFF Mode
					39 01 00 00 00 00 06 F0 55 AA 52 08 00
					15 01 00 00 00 00 02 B2 11 */
				];
				qcom,mdss-dsi-hbm-on-command = [
					39 01 00 00 00 00 03 51 0F FF
				];
				qcom,mdss-dsi-normal-hbm-on-command = [
					39 01 00 00 00 00 03 51 0F FF
				];
				qcom,mdss-dsi-hbm-enter-switch-command = [
					39 01 00 00 00 00 03 51 0F FF
				];
				qcom,mdss-dsi-hbm-exit-switch-command = [
					/* HBM OFF Mode
					39 01 00 00 00 00 06 F0 55 AA 52 08 00
					15 01 00 00 00 00 02 B2 11 */
				];
				qcom,mdss-dsi-aor-restore-command = [
					/* AOR 16% */
					39 00 00 00 00 00 03 f0 5a 5a
					39 00 00 00 00 00 04 b0 00 01 bd
					39 00 00 00 00 00 02 bd 02
					39 00 00 00 00 00 04 b0 02 b9 65
					39 00 00 00 00 00 07 65 01 5e 01 5e 01 5e
					39 00 00 00 00 00 02 f7 0f
					39 01 00 00 00 00 03 f0 a5 a5
				];
				qcom,mdss-dsi-aod-high-mode-command = [
					/* AOD 50nit */
					39 01 00 00 00 00 06 F0 55 AA 52 08 00
					15 01 00 00 00 00 02 6F 26
					39 01 00 00 00 00 0B B4 04 A2 04 A2 04 A2 04 A2 04 A2
				];
				qcom,mdss-dsi-aod-low-mode-command = [
					/* AOD 10nit */
					39 01 00 00 00 00 06 F0 55 AA 52 08 00
					15 01 00 00 00 00 02 6F 26
					39 01 00 00 00 00 0B B4 08 8A 08 8A 08 8A 08 8A 08 8A
				];
				qcom,mdss-dsi-esd-switch-page-command = [
					39 01 00 00 00 00 05 FF AA 55 A5 81
					15 01 00 00 00 00 02 6F 0F
				];
				qcom,mdss-dsi-aod-hbm-on-command-state = "dsi_hs_mode";
				qcom,mdss-dsi-aod-hbm-off-command-state = "dsi_hs_mode";
				qcom,mdss-dsi-timing-switch-command-state = "dsi_hs_mode";
				qcom,mdss-dsi-on-command-state = "dsi_lp_mode";
				qcom,mdss-dsi-off-command-state = "dsi_hs_mode";
				qcom,mdss-dsi-seed-off-command-state = "dsi_hs_mode";
				qcom,mdss-dsi-seed-0-command-state = "dsi_hs_mode";
				qcom,mdss-dsi-seed-1-command-state = "dsi_hs_mode";
				qcom,mdss-dsi-seed-2-command-state = "dsi_hs_mode";
				qcom,mdss-dsi-loading-effect-1-command-state = "dsi_hs_mode";
				//qcom,mdss-dsi-loading-effect-2-command-state = "dsi_hs_mode";
				qcom,mdss-dsi-loading-effect-off-command-state = "dsi_hs_mode";
				qcom,mdss-dsi-hbm-on-command-state = "dsi_hs_mode";
				qcom,mdss-dsi-hbm-off-command-state = "dsi_hs_mode";
				qcom,mdss-dsi-aor-restore-command-state = "dsi_hs_mode";

				//qcom,lm-split = <540 540>;
				qcom,compression-mode = "dsc";
				//qcom,mdss-dsc-encoders = <2>;
				qcom,mdss-dsc-slice-height = <20>;
				qcom,mdss-dsc-slice-width = <1080>;
				qcom,mdss-dsc-slice-per-pkt = <1>;
				qcom,mdss-dsc-bit-per-component = <10>;
				qcom,mdss-dsc-bit-per-pixel = <10>;
				qcom,mdss-dsc-block-prediction-enable;
				qcom,mdss-dsi-panel-id1-command-state = "dsi_lp_mode";
				qcom,mdss-dsi-panel-read-register-open-state = "dsi_lp_mode";
				qcom,mdss-dsi-panel-read-register-close-state = "dsi_lp_mode";
			};
		};
	};
};

&soc {
	dsi_oplus21005_boe_1080_2400_dsc_cmd_dvt {
		qcom,dsi-display-active;
	};
};

&dsi_oplus21005_boe_1080_2400_dsc_cmd_dvt {
	qcom,panel-supply-entries = <&dsi_panel_oplus_boe_pwr_supply>;
	qcom,mdss-dsi-panel-controller = <&mdss_dsi0>;
	qcom,mdss-dsi-bl-pmic-control-type = "bl_ctrl_dcs";
	qcom,mdss-dsi-dc-backlight-level = <520>;
	qcom,mdss-dsi-bl-min-level = <1>;
	qcom,mdss-dsi-bl-normal-max-level = <3515>;
	qcom,mdss-dsi-bl-max-level = <4095>;
	qcom,mdss-brightness-normal-max-level = <3515>;
	qcom,mdss-brightness-max-level = <4095>;
	qcom,mdss-brightness-default-level = <1680>;
	qcom,platform-te-gpio = <&tlmm 82 0>;
	qcom,platform-reset-gpio = <&tlmm 24 0>;
	qcom,platform-panel-vout-gpio = <&tlmm 25 0>;
	qcom,platform-panel-vddr-aod-en-gpio = <&tlmm 93 0>;

	qcom,ulps-enabled;
	qcom,dsi-select-clocks = "mux_byte_clk0", "mux_pixel_clk0";

	oplus,dsi-fod-brightness = <36 0xed>,
			<60 0xec>,
			<90 0xeb>,
			<140 0xea>,
			<200 0xe8>,
			<300 0xe4>,
			<458 0xe0>,
			<605 0xdb>,
			<743 0xcf>,
			<912 0xc8>,
			<1062 0xbf>,
			<1187 0xb6>,
			<1393 0xa0>,
			<1611 0x9b>,
			<1787 0x92>,
			<2000 0x8b>,
			<2200 0x80>,
			<2400 0x70>,
			<2600 0x60>,
			<2800 0x50>,
			<3000 0x4A>,
			<3200 0x40>,
			<3400 0x36>,
			<3515 0x2e>;
	oplus,dsi-dc-brightness = <0 0xff>,
			<2 0xFC>,
			<4 0xF9>,
			<6 0xF9>,
			<8 0xF8>,
			<10 0xF7>,
			<15 0xF6>,
			<20 0xF4>,
			<30 0xF0>,
			<40 0xEB>,
			<50 0xE6>,
			<60 0xE1>,
			<70 0xDD>,
			<80 0xD8>,
			<100 0xCF>,
			<120 0xC5>,
			<150 0xB9>,
			<200 0xA2>,
			<250 0x8C>,
			<300 0x76>,
			<350 0x5B>,
			<400 0x44>,
			<450 0x2C>,
			<500 0x0D>,
			<520 0x00>;


	qcom,mdss-dsi-display-timings {
		timing@sdc_fhd_120 { /* FHD+ 90hz 412.8Mhz 825.6Mbps  */
			//qcom,mdss-dsi-panel-phy-timings = [00 1B 07 06 16 15 07 07 07 02 04 00 17 0B];
			//qcom,mdss-dsi-panel-phy-timings = [00 21 08 08 19 17 08 08 09 02 04 00 1C 0D];// 480.4M
			//qcom,mdss-dsi-panel-phy-timings = [00 1E 08 07 18 16 08 08 08 02 04 00 1A 0C];// 450M
			qcom,mdss-dsi-panel-phy-timings = [00 24 0A 0A 1A 19 09 0A 09 02 04 00 1E 0F];//549M
			qcom,display-topology = <1 1 1>;
			qcom,default-topology-index = <0>;
		};
		timing@sdc_fhd_90 { /* FHD+ 90hz 412.8Mhz 825.6Mbps  */
			//qcom,mdss-dsi-panel-phy-timings = [00 16 05 05 14 1F 05 05 06 02 04 00 13 0A];
			//qcom,mdss-dsi-panel-phy-timings = [00 21 08 08 19 17 08 08 09 02 04 00 1C 0D];// 480.4M
			//qcom,mdss-dsi-panel-phy-timings = [00 1E 08 07 18 16 08 08 08 02 04 00 1A 0C];// 450M
			qcom,mdss-dsi-panel-phy-timings = [00 24 0A 0A 1A 19 09 0A 09 02 04 00 1E 0F];//549M
			qcom,display-topology = <1 1 1>;
			qcom,default-topology-index = <0>;
		};
		timing@sdc_fhd_60 { /* FHD+ 60hz 412.8Mhz 825.6Mbps */
			//qcom,mdss-dsi-panel-phy-timings = [00 10 03 03 11 1E 04 04 03 02 04 00 0E 08];
			//qcom,mdss-dsi-panel-phy-timings = [00 21 08 08 19 17 08 08 09 02 04 00 1C 0D];// 480.4M
			//qcom,mdss-dsi-panel-phy-timings = [00 1E 08 07 18 16 08 08 08 02 04 00 1A 0C];// 450M
			qcom,mdss-dsi-panel-phy-timings = [00 24 0A 0A 1A 19 09 0A 09 02 04 00 1E 0F];//549M
			qcom,display-topology = <1 1 1>;
			qcom,default-topology-index = <0>;
		};
	};
};
&dsi_oplus21005_boe_1080_2400_dsc_cmd_dvt {
	qcom,panel_voltage_vddi_name = "vddio";
	qcom,panel_voltage_vddi = <0 1800000 1850000 1950000>;
	qcom,panel_voltage_vddr_name = "vddio";
	qcom,panel_voltage_vddr = <1 1800000 1850000 1950000>;
};

&dsi_oplus21005_boe_1080_2400_dsc_cmd_dvt {
	oplus,apollo_backlight_enable;
	oplus,apollo-sync-brightness-level = <1300>;
};

&dsi_oplus21005_boe_1080_2400_dsc_cmd_dvt {
	oplus,color_vivid_status;
	oplus,color_srgb_status;
	oplus,color_softiris_status;
	oplus,color_dual_brightness_status;
};
